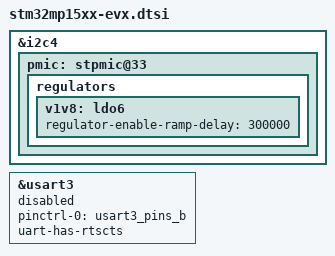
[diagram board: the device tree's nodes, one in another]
// SPDX-License-Identifier: (GPL-2.0+ OR BSD-3-Clause)
/*
 * Copyright (C) STMicroelectronics 2017 - All Rights Reserved
 * Author: Ludovic Barre <ludovic.barre@st.com> for STMicroelectronics.
 */


&i2c4 {
	pmic: stpmic@33 {
		regulators {
			v1v8: ldo6 {
				regulator-enable-ramp-delay = <300000>;
			};
		};
	};
};

&usart3 {
	pinctrl-names = "default";
	pinctrl-0 = <&usart3_pins_b>;
	uart-has-rtscts;
	status = "disabled";
};
